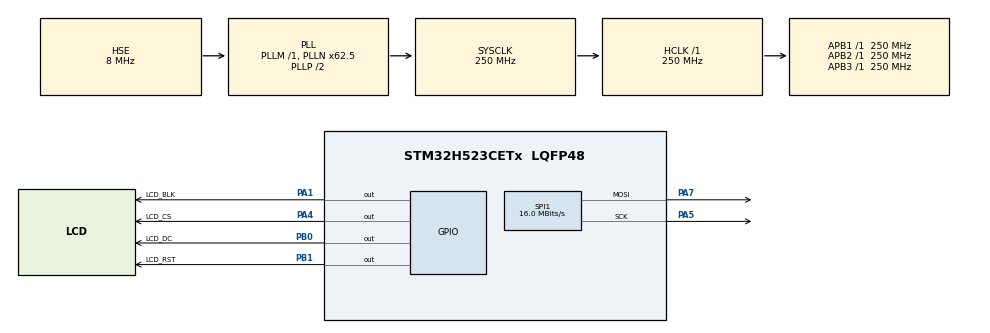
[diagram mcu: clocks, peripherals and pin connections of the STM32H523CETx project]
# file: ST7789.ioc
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CORTEX_M33_NS.Number-Cortex_Memory_Protection_Unit_Region0_OTP_RO_AREAS_Settings=MPU_REGION_NUMBER0
CORTEX_M33_NS.default_mode_Activation=1
CORTEX_M33_NS.userName=CORTEX_M33
GPDMA1.DESTDATAWIDTH_GPDMACH0=DMA_DEST_DATAWIDTH_HALFWORD
GPDMA1.DIRECTION_GPDMACH0=DMA_MEMORY_TO_PERIPH
GPDMA1.IPHANDLE_GPDMACH0-SIMPLEREQUEST_GPDMACH0=__NULL
GPDMA1.REQUEST_GPDMACH0=GPDMA1_REQUEST_SPI1_TX
GPDMA1.SRCDATAWIDTH_GPDMACH0=DMA_SRC_DATAWIDTH_HALFWORD
GPDMA1.SRCINC_GPDMACH0=DMA_SINC_INCREMENTED
Mcu.Family=STM32H5
Mcu.Name=STM32H523CETx
Mcu.Package=LQFP48
NVIC.GPDMA1_Channel0_IRQn=true\:0\:0\:false\:false\:true\:false\:true\:true
NVIC.PriorityGroup=NVIC_PRIORITYGROUP_4
NVIC.SPI1_IRQn=true\:0\:0\:false\:false\:true\:true\:true\:true
NVIC.TIM6_IRQn=true\:0\:0\:false\:false\:true\:true\:true\:true
PA1.GPIO_Label=LCD_BLK
PA1.GPIO_Speed=GPIO_SPEED_FREQ_VERY_HIGH
PA1.PinState=GPIO_PIN_RESET
PA1.Signal=GPIO_Output
PA13(JTMS/SWDIO).Mode=Serial_Wire
PA13(JTMS/SWDIO).Signal=DEBUG_JTMS-SWDIO
PA14(JTCK/SWCLK).Mode=Serial_Wire
PA14(JTCK/SWCLK).Signal=DEBUG_JTCK-SWCLK
PA4.GPIO_Label=LCD_CS
PA4.GPIO_Speed=GPIO_SPEED_FREQ_VERY_HIGH
PA4.PinState=GPIO_PIN_SET
PA4.Signal=GPIO_Output
PA5.Mode=TX_Only_Simplex_Unidirect_Master
PA5.Signal=SPI1_SCK
PA7.Mode=TX_Only_Simplex_Unidirect_Master
PA7.Signal=SPI1_MOSI
PB0.GPIO_Label=LCD_DC
PB0.GPIO_Speed=GPIO_SPEED_FREQ_VERY_HIGH
PB0.PinState=GPIO_PIN_SET
PB0.Signal=GPIO_Output
PB1.GPIO_Label=LCD_RST
PB1.GPIO_Speed=GPIO_SPEED_FREQ_VERY_HIGH
PB1.PinState=GPIO_PIN_SET
PB1.Signal=GPIO_Output
PC14-OSC32_IN(OSC32_IN).Mode=LSE-External-Oscillator
PC14-OSC32_IN(OSC32_IN).Signal=RCC_OSC32_IN
PC15-OSC32_OUT(OSC32_OUT).Mode=LSE-External-Oscillator
PC15-OSC32_OUT(OSC32_OUT).Signal=RCC_OSC32_OUT
PH0-OSC_IN(PH0).Mode=HSE-External-Oscillator
PH0-OSC_IN(PH0).Signal=RCC_OSC_IN
PH1-OSC_OUT(PH1).Mode=HSE-External-Oscillator
PH1-OSC_OUT(PH1).Signal=RCC_OSC_OUT
ProjectManager.HeapSize=0x200
ProjectManager.StackSize=0x400
ProjectManager.TargetToolchain=STM32CubeIDE
RCC.ADCFreq_Value=250000000
RCC.AHBFreq_Value=250000000
RCC.APB1Freq_Value=250000000
RCC.APB1TimFreq_Value=250000000
RCC.APB2Freq_Value=250000000
RCC.APB2TimFreq_Value=250000000
RCC.APB3Freq_Value=250000000
RCC.CSI_VALUE=4000000
RCC.CortexFreq_Value=250000000
RCC.EPOD_VALUE=8000000
RCC.HCLKFreq_Value=250000000
RCC.HSE_VALUE=8000000
RCC.HSI48_VALUE=48000000
RCC.HSI_VALUE=64000000
RCC.LSIRC_VALUE=32000
RCC.PLL2FRACN=0
RCC.PLL3FRACN=0
RCC.PLLFRACN=4096
RCC.PLLN=62
RCC.PLLSourceVirtual=RCC_PLL1_SOURCE_HSE
RCC.SPI1CLockSelection=RCC_SPI1CLKSOURCE_CLKP
RCC.SYSCLKFreq_VALUE=250000000
RCC.SYSCLKSource=RCC_SYSCLKSOURCE_PLLCLK
RCC.USBFreq_Value=48000000
RCC.VCOOutputFreq_Value=500000000
SPI1.BaudRatePrescaler=SPI_BAUDRATEPRESCALER_2
SPI1.CalculateBaudRate=16.0 MBits/s
SPI1.DataSize=SPI_DATASIZE_16BIT
SPI1.Direction=SPI_DIRECTION_2LINES_TXONLY
SPI1.Mode=SPI_MODE_MASTER
SPI1.VirtualType=VM_MASTER
STMicroelectronics.X-CUBE-TOUCHGFX.4.26.1.ApplicationCcGraphicsJjApplication=TouchGFXOoGenerator
STMicroelectronics.X-CUBE-TOUCHGFX.4.26.1.tgfx_block_size=4800
STMicroelectronics.X-CUBE-TOUCHGFX.4.26.1.tgfx_buffering_strategy=Partial
STMicroelectronics.X-CUBE-TOUCHGFX.4.26.1.tgfx_custom_height=240
STMicroelectronics.X-CUBE-TOUCHGFX.4.26.1.tgfx_custom_width=240
STMicroelectronics.X-CUBE-TOUCHGFX.4.26.1_IsPackSelfContextualization=true
TIM6.PeriodNoDither=1666
TIM6.Prescaler=2499
VP_BOOTPATH_VS_BOOTPATH.Mode=BP_Activate
VP_CORTEX_M33_NS_VS_Hclk.Mode=Hclk_Mode
VP_CRC_VS_CRC.Mode=CRC_Activate
VP_GPDMA1_VS_GPDMACH0.Mode=SIMPLEREQUEST_GPDMACH0
VP_ICACHE_VS_ICACHE.Mode=DirectMappedCache
VP_MEMORYMAP_VS_MEMORYMAP.Mode=CurAppReg
VP_PWR_VS_LPOM.Mode=PowerOptimisation
VP_PWR_VS_SECSignals.Mode=Security/Privilege
VP_STMicroelectronics.X-CUBE-TOUCHGFX_VS_GraphicsJjApplication_4.26.1.Mode=GraphicsJjApplication
VP_TIM6_VS_ClockSourceINT.Mode=Enable_Timer
board=custom

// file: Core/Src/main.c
/* USER CODE BEGIN Header */
/**
  ******************************************************************************
  * @file           : main.c
  * @brief          : Main program body
  ******************************************************************************
  * @attention
  *
  * Copyright (c) 2026 STMicroelectronics.
  * All rights reserved.
  *
  * This software is licensed under terms that can be found in the LICENSE file
  * in the root directory of this software component.
  * If no LICENSE file comes with this software, it is provided AS-IS.
  *
  ******************************************************************************
  */
/* USER CODE END Header */
#include "main.h"
#include "app_touchgfx.h"

/* USER CODE BEGIN Includes */
#include "st7789.h"
/* USER CODE END Includes */

CRC_HandleTypeDef hcrc;

SPI_HandleTypeDef hspi1;
DMA_HandleTypeDef handle_GPDMA1_Channel0;

TIM_HandleTypeDef htim6;

void SystemClock_Config(void);
void PeriphCommonClock_Config(void);
static void MPU_Config(void);
static void MX_GPIO_Init(void);
static void MX_GPDMA1_Init(void);
static void MX_ICACHE_Init(void);
static void MX_SPI1_Init(void);
static void MX_CRC_Init(void);
static void MX_TIM6_Init(void);

/* USER CODE BEGIN 0 */
extern void touchgfxSignalVSync(void);   /* TouchGFX sinh ra */
/* USER CODE END 0 */

int main(void)
{

  /* MCU Configuration--------------------------------------------------------*/

  /* MPU Configuration--------------------------------------------------------*/
  MPU_Config();

  /* Reset of all peripherals, Initializes the Flash interface and the Systick. */
  HAL_Init();

  /* Configure the system clock */
  SystemClock_Config();

  /* Configure the peripherals common clocks */
  PeriphCommonClock_Config();

  /* Initialize all configured peripherals */
  MX_GPIO_Init();
  MX_GPDMA1_Init();
  MX_ICACHE_Init();
  MX_SPI1_Init();
  MX_CRC_Init();
  MX_TIM6_Init();
  MX_TouchGFX_Init();
  /* USER CODE BEGIN 2 */
  HAL_TIM_Base_Start_IT(&htim6);   /* nhip VSync 60 Hz */
  /* USER CODE END 2 */

  /* Infinite loop */
  while (1)
  {

  MX_TouchGFX_Process();
  }
}

void SystemClock_Config(void)
{
  RCC_OscInitTypeDef RCC_OscInitStruct = {0};
  RCC_ClkInitTypeDef RCC_ClkInitStruct = {0};

  /** Configure the main internal regulator output voltage
  */
  __HAL_PWR_VOLTAGESCALING_CONFIG(PWR_REGULATOR_VOLTAGE_SCALE0);

  while(!__HAL_PWR_GET_FLAG(PWR_FLAG_VOSRDY)) {}

  /** Initializes the RCC Oscillators according to the specified parameters
  * in the RCC_OscInitTypeDef structure.
  */
  RCC_OscInitStruct.OscillatorType = RCC_OSCILLATORTYPE_HSI|RCC_OSCILLATORTYPE_HSE;
  RCC_OscInitStruct.HSEState = RCC_HSE_ON;
  RCC_OscInitStruct.HSIState = RCC_HSI_ON;
  RCC_OscInitStruct.HSIDiv = RCC_HSI_DIV2;
  RCC_OscInitStruct.HSICalibrationValue = RCC_HSICALIBRATION_DEFAULT;
  RCC_OscInitStruct.PLL.PLLState = RCC_PLL_ON;
  RCC_OscInitStruct.PLL.PLLSource = RCC_PLL1_SOURCE_HSE;
  RCC_OscInitStruct.PLL.PLLM = 1;
  RCC_OscInitStruct.PLL.PLLN = 62;
  RCC_OscInitStruct.PLL.PLLP = 2;
  RCC_OscInitStruct.PLL.PLLQ = 2;
  RCC_OscInitStruct.PLL.PLLR = 2;
  RCC_OscInitStruct.PLL.PLLRGE = RCC_PLL1_VCIRANGE_3;
  RCC_OscInitStruct.PLL.PLLVCOSEL = RCC_PLL1_VCORANGE_WIDE;
  RCC_OscInitStruct.PLL.PLLFRACN = 4096;
  if (HAL_RCC_OscConfig(&RCC_OscInitStruct) != HAL_OK)
  {
    Error_Handler();
  }

  /** Initializes the CPU, AHB and APB buses clocks
  */
  RCC_ClkInitStruct.ClockType = RCC_CLOCKTYPE_HCLK|RCC_CLOCKTYPE_SYSCLK
                              |RCC_CLOCKTYPE_PCLK1|RCC_CLOCKTYPE_PCLK2
                              |RCC_CLOCKTYPE_PCLK3;
  RCC_ClkInitStruct.SYSCLKSource = RCC_SYSCLKSOURCE_PLLCLK;
  RCC_ClkInitStruct.AHBCLKDivider = RCC_SYSCLK_DIV1;
  RCC_ClkInitStruct.APB1CLKDivider = RCC_HCLK_DIV1;
  RCC_ClkInitStruct.APB2CLKDivider = RCC_HCLK_DIV1;
  RCC_ClkInitStruct.APB3CLKDivider = RCC_HCLK_DIV1;

  if (HAL_RCC_ClockConfig(&RCC_ClkInitStruct, FLASH_LATENCY_5) != HAL_OK)
  {
    Error_Handler();
  }

  /** Configure the programming delay
  */
  __HAL_FLASH_SET_PROGRAM_DELAY(FLASH_PROGRAMMING_DELAY_2);
}

void PeriphCommonClock_Config(void)
{
  RCC_PeriphCLKInitTypeDef PeriphClkInitStruct = {0};

  /** Initializes the peripherals clock
  */
  PeriphClkInitStruct.PeriphClockSelection = RCC_PERIPHCLK_CKPER;
  PeriphClkInitStruct.CkperClockSelection = RCC_CLKPSOURCE_HSI;
  if (HAL_RCCEx_PeriphCLKConfig(&PeriphClkInitStruct) != HAL_OK)
  {
    Error_Handler();
  }
}

static void MX_CRC_Init(void)
{

  hcrc.Instance = CRC;
  hcrc.Init.DefaultPolynomialUse = DEFAULT_POLYNOMIAL_ENABLE;
  hcrc.Init.DefaultInitValueUse = DEFAULT_INIT_VALUE_ENABLE;
  hcrc.Init.InputDataInversionMode = CRC_INPUTDATA_INVERSION_NONE;
  hcrc.Init.OutputDataInversionMode = CRC_OUTPUTDATA_INVERSION_DISABLE;
  hcrc.InputDataFormat = CRC_INPUTDATA_FORMAT_BYTES;
  if (HAL_CRC_Init(&hcrc) != HAL_OK)
  {
    Error_Handler();
  }

}

static void MX_GPDMA1_Init(void)
{

  /* Peripheral clock enable */
  __HAL_RCC_GPDMA1_CLK_ENABLE();

  /* GPDMA1 interrupt Init */
    HAL_NVIC_SetPriority(GPDMA1_Channel0_IRQn, 0, 0);
    HAL_NVIC_EnableIRQ(GPDMA1_Channel0_IRQn);

}

static void MX_ICACHE_Init(void)
{

  /** Enable instruction cache in 1-way (direct mapped cache)
  */
  if (HAL_ICACHE_ConfigAssociativityMode(ICACHE_1WAY) != HAL_OK)
  {
    Error_Handler();
  }
  if (HAL_ICACHE_Enable() != HAL_OK)
  {
    Error_Handler();
  }

}

static void MX_SPI1_Init(void)
{

  /* SPI1 parameter configuration*/
  hspi1.Instance = SPI1;
  hspi1.Init.Mode = SPI_MODE_MASTER;
  hspi1.Init.Direction = SPI_DIRECTION_2LINES_TXONLY;
  hspi1.Init.DataSize = SPI_DATASIZE_16BIT;
  hspi1.Init.CLKPolarity = SPI_POLARITY_LOW;
  hspi1.Init.CLKPhase = SPI_PHASE_1EDGE;
  hspi1.Init.NSS = SPI_NSS_SOFT;
  hspi1.Init.BaudRatePrescaler = SPI_BAUDRATEPRESCALER_2;
  hspi1.Init.FirstBit = SPI_FIRSTBIT_MSB;
  hspi1.Init.TIMode = SPI_TIMODE_DISABLE;
  hspi1.Init.CRCCalculation = SPI_CRCCALCULATION_DISABLE;
  hspi1.Init.CRCPolynomial = 0x7;
  hspi1.Init.NSSPMode = SPI_NSS_PULSE_ENABLE;
  hspi1.Init.NSSPolarity = SPI_NSS_POLARITY_LOW;
  hspi1.Init.FifoThreshold = SPI_FIFO_THRESHOLD_01DATA;
  hspi1.Init.MasterSSIdleness = SPI_MASTER_SS_IDLENESS_00CYCLE;
  hspi1.Init.MasterInterDataIdleness = SPI_MASTER_INTERDATA_IDLENESS_00CYCLE;
  hspi1.Init.MasterReceiverAutoSusp = SPI_MASTER_RX_AUTOSUSP_DISABLE;
  hspi1.Init.MasterKeepIOState = SPI_MASTER_KEEP_IO_STATE_DISABLE;
  hspi1.Init.IOSwap = SPI_IO_SWAP_DISABLE;
  hspi1.Init.ReadyMasterManagement = SPI_RDY_MASTER_MANAGEMENT_INTERNALLY;
  hspi1.Init.ReadyPolarity = SPI_RDY_POLARITY_HIGH;
  if (HAL_SPI_Init(&hspi1) != HAL_OK)
  {
    Error_Handler();
  }
  /* USER CODE BEGIN SPI1_Init 2 */
  ST7789_Init();
  /* USER CODE END SPI1_Init 2 */

}

static void MX_TIM6_Init(void)
{

  TIM_MasterConfigTypeDef sMasterConfig = {0};

  htim6.Instance = TIM6;
  htim6.Init.Prescaler = 2499;
  htim6.Init.CounterMode = TIM_COUNTERMODE_UP;
  htim6.Init.Period = 1666;
  htim6.Init.AutoReloadPreload = TIM_AUTORELOAD_PRELOAD_DISABLE;
  if (HAL_TIM_Base_Init(&htim6) != HAL_OK)
  {
    Error_Handler();
  }
  sMasterConfig.MasterOutputTrigger = TIM_TRGO_RESET;
  sMasterConfig.MasterSlaveMode = TIM_MASTERSLAVEMODE_DISABLE;
  if (HAL_TIMEx_MasterConfigSynchronization(&htim6, &sMasterConfig) != HAL_OK)
  {
    Error_Handler();
  }

}

static void MX_GPIO_Init(void)
{
  GPIO_InitTypeDef GPIO_InitStruct = {0};

  /* GPIO Ports Clock Enable */
  __HAL_RCC_GPIOC_CLK_ENABLE();
  __HAL_RCC_GPIOH_CLK_ENABLE();
  __HAL_RCC_GPIOA_CLK_ENABLE();
  __HAL_RCC_GPIOB_CLK_ENABLE();

  /*Configure GPIO pin Output Level */
  HAL_GPIO_WritePin(LCD_BLK_GPIO_Port, LCD_BLK_Pin, GPIO_PIN_RESET);

  /*Configure GPIO pin Output Level */
  HAL_GPIO_WritePin(LCD_CS_GPIO_Port, LCD_CS_Pin, GPIO_PIN_SET);

  /*Configure GPIO pin Output Level */
  HAL_GPIO_WritePin(GPIOB, LCD_DC_Pin|LCD_RST_Pin, GPIO_PIN_SET);

  /*Configure GPIO pins : LCD_BLK_Pin LCD_CS_Pin */
  GPIO_InitStruct.Pin = LCD_BLK_Pin|LCD_CS_Pin;
  GPIO_InitStruct.Mode = GPIO_MODE_OUTPUT_PP;
  GPIO_InitStruct.Pull = GPIO_NOPULL;
  GPIO_InitStruct.Speed = GPIO_SPEED_FREQ_VERY_HIGH;
  HAL_GPIO_Init(GPIOA, &GPIO_InitStruct);

  /*Configure GPIO pins : LCD_DC_Pin LCD_RST_Pin */
  GPIO_InitStruct.Pin = LCD_DC_Pin|LCD_RST_Pin;
  GPIO_InitStruct.Mode = GPIO_MODE_OUTPUT_PP;
  GPIO_InitStruct.Pull = GPIO_NOPULL;
  GPIO_InitStruct.Speed = GPIO_SPEED_FREQ_VERY_HIGH;
  HAL_GPIO_Init(GPIOB, &GPIO_InitStruct);

}

/* USER CODE BEGIN 4 */
void HAL_TIM_PeriodElapsedCallback(TIM_HandleTypeDef *htim)
{
  if (htim->Instance == TIM6)
  {
    touchgfxSignalVSync();
  }
}
/* USER CODE END 4 */

 /* MPU Configuration */

void MPU_Config(void)
{
  MPU_Region_InitTypeDef MPU_InitStruct = {0};
  MPU_Attributes_InitTypeDef MPU_AttributesInit = {0};

  /* Disables the MPU */
  HAL_MPU_Disable();

  /** Initializes and configures the Region 0 and the memory to be protected
  */
  MPU_InitStruct.Enable = MPU_REGION_ENABLE;
  MPU_InitStruct.Number = MPU_REGION_NUMBER0;
  MPU_InitStruct.BaseAddress = 0x08FFF000;
  MPU_InitStruct.LimitAddress = 0x08FFFFFF;
  MPU_InitStruct.AttributesIndex = MPU_ATTRIBUTES_NUMBER0;
  MPU_InitStruct.AccessPermission = MPU_REGION_ALL_RO;
  MPU_InitStruct.DisableExec = MPU_INSTRUCTION_ACCESS_DISABLE;
  MPU_InitStruct.IsShareable = MPU_ACCESS_NOT_SHAREABLE;

  HAL_MPU_ConfigRegion(&MPU_InitStruct);

  /** Initializes and configures the Attribute 0 and the memory to be protected
  */
  MPU_AttributesInit.Number = MPU_ATTRIBUTES_NUMBER0;
  MPU_AttributesInit.Attributes = INNER_OUTER(MPU_NOT_CACHEABLE);

  HAL_MPU_ConfigMemoryAttributes(&MPU_AttributesInit);
  /* Enables the MPU */
  HAL_MPU_Enable(MPU_PRIVILEGED_DEFAULT);

}

void Error_Handler(void)
{
  __disable_irq();
  while (1)
  {
  }
}
